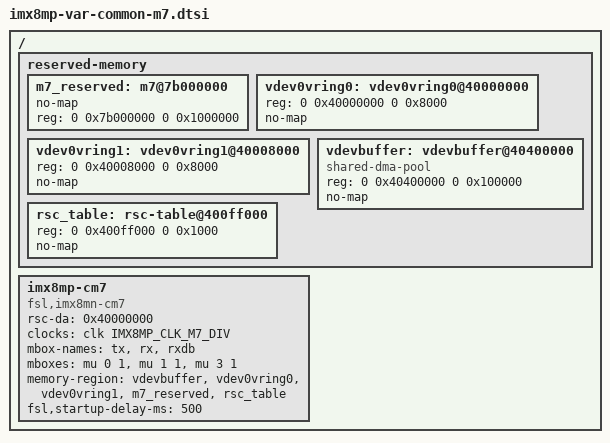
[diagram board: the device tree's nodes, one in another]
// SPDX-License-Identifier: (GPL-2.0 OR MIT)
/*
 * Copyright 2020 NXP
 * Copyright 2020-2025 Variscite Ltd.
 */

/ {
	reserved-memory {
		#address-cells = <2>;
		#size-cells = <2>;
		ranges;

		/*
		 * When modifying this region, update also
		 * M4_DDR_START and M4_DDR_END macros of the mcu_rdc
		 * node of the imx8mp-var-common-u-boot.dtsi U-Boot
		 * device tree.
		 *
		 * They are defined in imx8mp-sec-def.h and represent
		 * MRSA and MREA, respectively, of the RDC memory region.
		 *
		 * MRSA calculation:
		 * 0x7B000000 - 0x40000000 =  0x3B000000 // Desired Start - DDR Base
		 * 0x3B000000 / 2 = 0x1D800000           // Right-shift 1 bit
		 * MREA calculation:
		 * 0x7C000000 - 0x40000000 =  0x3C000000 // Desired End - DDR Base
		 * 0x3C000000 / 2 = 0x1E000000           // Right-shift 1 bit
		 */
		m7_reserved: m7@7b000000 {
			no-map;
			reg = <0 0x7b000000 0 0x1000000>;
		};

		vdev0vring0: vdev0vring0@40000000 {
			reg = <0 0x40000000 0 0x8000>;
			no-map;
		};

		vdev0vring1: vdev0vring1@40008000 {
			reg = <0 0x40008000 0 0x8000>;
			no-map;
		};

		vdevbuffer: vdevbuffer@40400000 {
			compatible = "shared-dma-pool";
			reg = <0 0x40400000 0 0x100000>;
			no-map;
		};

		rsc_table: rsc-table@400ff000 {
			reg = <0 0x400ff000 0 0x1000>;
			no-map;
		};
	};

	imx8mp-cm7 {
		compatible = "fsl,imx8mn-cm7";
		rsc-da = <0x40000000>;
		clocks = <&clk IMX8MP_CLK_M7_DIV>;
		mbox-names = "tx", "rx", "rxdb";
		mboxes = <&mu 0 1
			  &mu 1 1
			  &mu 3 1>;
		memory-region = <&vdevbuffer>, <&vdev0vring0>, <&vdev0vring1>, <&m7_reserved>, <&rsc_table>;
		fsl,startup-delay-ms = <500>;
		status = "okay";
	};
};
